# S32K312_M7 register map
Vendor: NXP Semiconductors; File version: 1.4
CPU: CM7 r0p1, little endian, MPU, FPU, VTOR, 4 interrupt priority bits
Registers are 32-bit, read-write, reset 0x0 unless marked. A register's access mark holds for its fields unless they carry their own. Offsets are from the block's base; [hi:lo] are bit positions; {n}, {i} and the like mark numbered series.

## EIM
Base 0x40258000
0x00 EIMCR — Error Injection Module Configuration Register
  [0] GEIEN — Global Error Injection Enable
    0=DISABLE (Disabled); 1=ENABLE (Enabled)
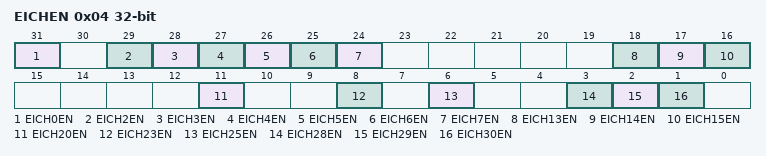
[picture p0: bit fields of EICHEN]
0x04 EICHEN — Error Injection Channel Enable register
  [31] EICH0EN — Error Injection Channel 0 Enable
    0=DISABLE (Error injection is disabled on Error Injection Channel 0); 1=ENABLE (Error injection is enabled on Error Injection Channel 0)
  [31-n] EICH{n}EN (n=2..7) — Error Injection Channel {n} Enable
    0=DISABLE (Error injection is disabled on Error Injection Channel {n}); 1=ENABLE (Error injection is enabled on Error Injection Channel {n})
  [18] EICH13EN — Error Injection Channel 13 Enable
    0=DISABLE (Error injection is disabled on Error Injection Channel 13); 1=ENABLE (Error injection is enabled on Error Injection Channel 13)
  [17] EICH14EN — Error Injection Channel 14 Enable
    0=DISABLE (Error injection is disabled on Error Injection Channel 14); 1=ENABLE (Error injection is enabled on Error Injection Channel 14)
  [16] EICH15EN — Error Injection Channel 15 Enable
    0=DISABLE (Error injection is disabled on Error Injection Channel 15); 1=ENABLE (Error injection is enabled on Error Injection Channel 15)
  [11] EICH20EN — Error Injection Channel 20 Enable
    0=DISABLE (Error injection is disabled on Error Injection Channel 20); 1=ENABLE (Error injection is enabled on Error Injection Channel 20)
  [8] EICH23EN — Error Injection Channel 23 Enable
    0=DISABLE (Error injection is disabled on Error Injection Channel 23); 1=ENABLE (Error injection is enabled on Error Injection Channel 23)
  [6] EICH25EN — Error Injection Channel 25 Enable
    0=DISABLE (Error injection is disabled on Error Injection Channel 25); 1=ENABLE (Error injection is enabled on Error Injection Channel 25)
  [3] EICH28EN — Error Injection Channel 28 Enable
    0=DISABLE (Error injection is disabled on Error Injection Channel 28); 1=ENABLE (Error injection is enabled on Error Injection Channel 28)
  [2] EICH29EN — Error Injection Channel 29 Enable
    0=DISABLE (Error injection is disabled on Error Injection Channel 29); 1=ENABLE (Error injection is enabled on Error Injection Channel 29)
  [1] EICH30EN — Error Injection Channel 30 Enable
    0=DISABLE (Error injection is disabled on Error Injection Channel 30); 1=ENABLE (Error injection is enabled on Error Injection Channel 30)
0x100 EICHD0_WORD0 — Error Injection Channel Descriptor 0, Word0
  [31:24] CHKBIT_MASK — Checkbit Mask
0x104 EICHD0_WORD1 — Error Injection Channel Descriptor 0, Word1
  [31:0] B0_3DATA_MASK — Data Mask Bytes 0-3
0x108 EICHD0_WORD2 — Error Injection Channel Descriptor 0, Word2
  [31:0] B4_7DATA_MASK — Data Mask Bytes 4-7
0x180 EICHD2_WORD0 — Error Injection Channel Descriptor 2, Word0
  [31:24] CHKBIT_MASK — Checkbit Mask
0x184 EICHD2_WORD1 — Error Injection Channel Descriptor 2, Word1
  [31:0] B0_3DATA_MASK — Data Mask Bytes 0-3
0x188 EICHD2_WORD2 — Error Injection Channel Descriptor 2, Word2
  [31:0] B4_7DATA_MASK — Data Mask Bytes 4-7
0x1C0 EICHD3_WORD0 — Error Injection Channel Descriptor 3, Word0
  [31:18] CHKBIT_MASK — Checkbit Mask
0x1C4 EICHD3_WORD1 — Error Injection Channel Descriptor 3, Word1
  [11:0] B0_3DATA_MASK — Data Mask Bytes 0-3
0x1C8 EICHD3_WORD2 — Error Injection Channel Descriptor 3, Word2
  [31:0] B4_7DATA_MASK — Data Mask Bytes 4-7
0x200 EICHD4_WORD0 — Error Injection Channel Descriptor 4, Word0
  [31:16] CHKBIT_MASK — Checkbit Mask
{0x200+4i} EICHD4_WORD{i} (i=1..4) — Error Injection Channel Descriptor 4, Word{i}
  [31:0] B{4i-4}_{4i-1}DATA_MASK — Data Mask Bytes {4i-4}-{4i-1}
{0x100+0x40*i} EICHD{i}_WORD0 (i=5..7) — Error Injection Channel Descriptor {i}, Word0
  [31:4] CHKBIT_MASK — Checkbit Mask
0x244 EICHD5_WORD1 — Error Injection Channel Descriptor 5, Word1
  [7:0] B0_3DATA_MASK — Data Mask Bytes 0-3
{0x240+4i} EICHD5_WORD{i} (i=2..4) — Error Injection Channel Descriptor 5, Word{i}
  [31:0] B{4i-4}_{4i-1}DATA_MASK — Data Mask Bytes {4i-4}-{4i-1}
{0x280+4i} EICHD6_WORD{i} (i=1..4) — Error Injection Channel Descriptor 6, Word{i}
  [31:0] B{4i-4}_{4i-1}DATA_MASK — Data Mask Bytes {4i-4}-{4i-1}
{0x2C0+4i} EICHD7_WORD{i} (i=1..4) — Error Injection Channel Descriptor 7, Word{i}
  [31:0] B{4i-4}_{4i-1}DATA_MASK — Data Mask Bytes {4i-4}-{4i-1}
{0x100+0x40*i} EICHD{i}_WORD0 (i=13..15) — Error Injection Channel Descriptor {i}, Word0
  [31:24] CHKBIT_MASK — Checkbit Mask
0x444 EICHD13_WORD1 — Error Injection Channel Descriptor 13, Word1
  [31:0] B0_3DATA_MASK — Data Mask Bytes 0-3
0x448 EICHD13_WORD2 — Error Injection Channel Descriptor 13, Word2
  [31:0] B4_7DATA_MASK — Data Mask Bytes 4-7
0x484 EICHD14_WORD1 — Error Injection Channel Descriptor 14, Word1
  [31:0] B0_3DATA_MASK — Data Mask Bytes 0-3
0x4C4 EICHD15_WORD1 — Error Injection Channel Descriptor 15, Word1
  [31:0] B0_3DATA_MASK — Data Mask Bytes 0-3
0x604 EICHD20_WORD1 — Error Injection Channel Descriptor 20, Word1
  [27:0] B0_3DATA_MASK — Data Mask Bytes 0-3
{0x600+4i} EICHD20_WORD{i} (i=2..6) — Error Injection Channel Descriptor 20, Word{i}
  [31:0] B{4i-4}_{4i-1}DATA_MASK — Data Mask Bytes {4i-4}-{4i-1}
0x6C4 EICHD23_WORD1 — Error Injection Channel Descriptor 23, Word1
  [27:0] B0_3DATA_MASK — Data Mask Bytes 0-3
0x6C8 EICHD23_WORD2 — Error Injection Channel Descriptor 23, Word2
  [31:0] B4_7DATA_MASK — Data Mask Bytes 4-7
0x744 EICHD25_WORD1 — Error Injection Channel Descriptor 25, Word1
  [27:0] B0_3DATA_MASK — Data Mask Bytes 0-3
0x748 EICHD25_WORD2 — Error Injection Channel Descriptor 25, Word2
  [31:0] B4_7DATA_MASK — Data Mask Bytes 4-7
0x804 EICHD28_WORD1 — Error Injection Channel Descriptor 28, Word1
  [23:0] B0_3DATA_MASK — Data Mask Bytes 0-3
0x844 EICHD29_WORD1 — Error Injection Channel Descriptor 29, Word1
  [17:0] B0_3DATA_MASK — Data Mask Bytes 0-3
0x884 EICHD30_WORD1 — Error Injection Channel Descriptor 30, Word1
  [17:0] B0_3DATA_MASK — Data Mask Bytes 0-3
